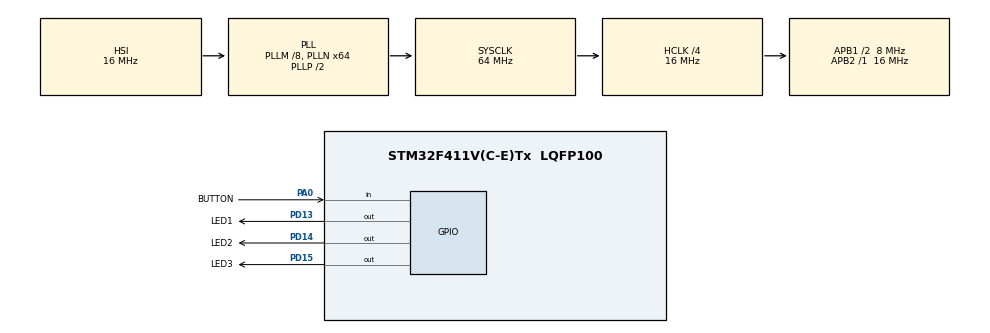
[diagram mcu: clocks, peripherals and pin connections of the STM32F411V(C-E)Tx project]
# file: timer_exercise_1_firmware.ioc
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Mcu.Family=STM32F4
Mcu.Name=STM32F411V(C-E)Tx
Mcu.Package=LQFP100
NVIC.PriorityGroup=NVIC_PRIORITYGROUP_4
NVIC.TIM2_IRQn=true\:0\:0\:false\:false\:true\:true\:true\:true
PA0-WKUP.GPIO_Label=BUTTON
PA0-WKUP.GPIO_PuPd=GPIO_PULLDOWN
PA0-WKUP.Signal=GPIO_Input
PA13.Mode=Serial_Wire
PA13.Signal=SYS_JTMS-SWDIO
PA14.Mode=Serial_Wire
PA14.Signal=SYS_JTCK-SWCLK
PD13.GPIO_Label=LED1
PD13.PinState=GPIO_PIN_SET
PD13.Signal=GPIO_Output
PD14.GPIO_Label=LED2
PD14.PinState=GPIO_PIN_SET
PD14.Signal=GPIO_Output
PD15.GPIO_Label=LED3
PD15.PinState=GPIO_PIN_SET
PD15.Signal=GPIO_Output
PH0\ -\ OSC_IN.Mode=HSE-External-Oscillator
PH0\ -\ OSC_IN.Signal=RCC_OSC_IN
PH1\ -\ OSC_OUT.Mode=HSE-External-Oscillator
PH1\ -\ OSC_OUT.Signal=RCC_OSC_OUT
ProjectManager.HeapSize=0x200
ProjectManager.StackSize=0x400
ProjectManager.TargetToolchain=STM32CubeIDE
RCC.48MHZClocksFreq_Value=32000000
RCC.AHBCLKDivider=RCC_SYSCLK_DIV4
RCC.AHBFreq_Value=16000000
RCC.APB1CLKDivider=RCC_HCLK_DIV2
RCC.APB1Freq_Value=8000000
RCC.APB1TimFreq_Value=16000000
RCC.APB2Freq_Value=16000000
RCC.APB2TimFreq_Value=16000000
RCC.CortexFreq_Value=16000000
RCC.HCLKFreq_Value=16000000
RCC.HSE_VALUE=25000000
RCC.HSI_VALUE=16000000
RCC.LSE_VALUE=32768
RCC.PLLM=8
RCC.PLLN=64
RCC.SYSCLKFreq_VALUE=64000000
RCC.SYSCLKSource=RCC_SYSCLKSOURCE_PLLCLK
RCC.VCOOutputFreq_Value=128000000
TIM2.Period=4999
TIM2.Prescaler=1599
VP_TIM2_VS_ClockSourceINT.Mode=Internal
board=custom

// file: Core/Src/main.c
/* USER CODE BEGIN Header */
/**
  ******************************************************************************
  * @file           : main.c
  * @brief          : Main program body
  ******************************************************************************
  * @attention
  *
  * Copyright (c) 2024 STMicroelectronics.
  * All rights reserved.
  *
  * This software is licensed under terms that can be found in the LICENSE file
  * in the root directory of this software component.
  * If no LICENSE file comes with this software, it is provided AS-IS.
  *
  ******************************************************************************
  */
/* USER CODE END Header */
#include "main.h"
#include "system/sys_manage.h"

#define NUMBER_OF_LEDS 3

bsp_gpio_t LED[NUMBER_OF_LEDS] = {
    {GPIOD, GPIO_PIN_13, 0, GPIO_MODE_OUTPUT_PP},
    {GPIOD, GPIO_PIN_14, 0, GPIO_MODE_OUTPUT_PP},
    {GPIOD, GPIO_PIN_15, 0, GPIO_MODE_OUTPUT_PP},
};

bsp_gpio_t BUTTON = {GPIOA, GPIO_PIN_0, 0, GPIO_MODE_INPUT};

TIM_HandleTypeDef htim2;
bool timer_flag = 0;

static sys_button_evt_t button_evt = BUTTON_EVT_NONE;

void SystemClock_Config(void);
static void MX_GPIO_Init(void);
static void MX_TIM2_Init(void);
void HAL_TIM_PeriodElapsedCallback(TIM_HandleTypeDef *htim);

int main(void)
{

  /* MCU Configuration--------------------------------------------------------*/

  /* Reset of all peripherals, Initializes the Flash interface and the Systick. */
  HAL_Init();

  /* Configure the system clock */
  SystemClock_Config();

  /* Initialize all configured peripherals */
  MX_GPIO_Init();
  MX_TIM2_Init();
  /* USER CODE BEGIN 2 */
  sys_init(&BUTTON, LED, LED_ACTIVE_LEVEL_HIGH, &htim2, 1599, 4999);
  /* USER CODE END 2 */

  /* Infinite loop */
  while (1)
  {
	button_evt = sys_button_fsm(&BUTTON);
	sys_manage_fsm(LED, LED_ACTIVE_LEVEL_HIGH, button_evt, &timer_flag);
  }
}

/**
  * @brief Callback Function of timer interrupt
  * @retval None
  */
void HAL_TIM_PeriodElapsedCallback(TIM_HandleTypeDef *htim)
{
  if (htim->Instance == TIM2)
  {
	timer_flag = 1;
  }
}

void SystemClock_Config(void)
{
  RCC_OscInitTypeDef RCC_OscInitStruct = {0};
  RCC_ClkInitTypeDef RCC_ClkInitStruct = {0};

  /** Configure the main internal regulator output voltage
  */
  __HAL_RCC_PWR_CLK_ENABLE();
  __HAL_PWR_VOLTAGESCALING_CONFIG(PWR_REGULATOR_VOLTAGE_SCALE1);

  /** Initializes the RCC Oscillators according to the specified parameters
  * in the RCC_OscInitTypeDef structure.
  */
  RCC_OscInitStruct.OscillatorType = RCC_OSCILLATORTYPE_HSI;
  RCC_OscInitStruct.HSIState = RCC_HSI_ON;
  RCC_OscInitStruct.HSICalibrationValue = RCC_HSICALIBRATION_DEFAULT;
  RCC_OscInitStruct.PLL.PLLState = RCC_PLL_ON;
  RCC_OscInitStruct.PLL.PLLSource = RCC_PLLSOURCE_HSI;
  RCC_OscInitStruct.PLL.PLLM = 8;
  RCC_OscInitStruct.PLL.PLLN = 64;
  RCC_OscInitStruct.PLL.PLLP = RCC_PLLP_DIV2;
  RCC_OscInitStruct.PLL.PLLQ = 4;
  if (HAL_RCC_OscConfig(&RCC_OscInitStruct) != HAL_OK)
  {
    Error_Handler();
  }

  /** Initializes the CPU, AHB and APB buses clocks
  */
  RCC_ClkInitStruct.ClockType = RCC_CLOCKTYPE_HCLK|RCC_CLOCKTYPE_SYSCLK
                              |RCC_CLOCKTYPE_PCLK1|RCC_CLOCKTYPE_PCLK2;
  RCC_ClkInitStruct.SYSCLKSource = RCC_SYSCLKSOURCE_PLLCLK;
  RCC_ClkInitStruct.AHBCLKDivider = RCC_SYSCLK_DIV4;
  RCC_ClkInitStruct.APB1CLKDivider = RCC_HCLK_DIV2;
  RCC_ClkInitStruct.APB2CLKDivider = RCC_HCLK_DIV1;

  if (HAL_RCC_ClockConfig(&RCC_ClkInitStruct, FLASH_LATENCY_0) != HAL_OK)
  {
    Error_Handler();
  }
}

static void MX_TIM2_Init(void)
{

  TIM_ClockConfigTypeDef sClockSourceConfig = {0};
  TIM_MasterConfigTypeDef sMasterConfig = {0};

  htim2.Instance = TIM2;
  htim2.Init.Prescaler = 1599;
  htim2.Init.CounterMode = TIM_COUNTERMODE_UP;
  htim2.Init.Period = 4999;
  htim2.Init.ClockDivision = TIM_CLOCKDIVISION_DIV1;
  htim2.Init.AutoReloadPreload = TIM_AUTORELOAD_PRELOAD_DISABLE;
  if (HAL_TIM_Base_Init(&htim2) != HAL_OK)
  {
    Error_Handler();
  }
  sClockSourceConfig.ClockSource = TIM_CLOCKSOURCE_INTERNAL;
  if (HAL_TIM_ConfigClockSource(&htim2, &sClockSourceConfig) != HAL_OK)
  {
    Error_Handler();
  }
  sMasterConfig.MasterOutputTrigger = TIM_TRGO_RESET;
  sMasterConfig.MasterSlaveMode = TIM_MASTERSLAVEMODE_DISABLE;
  if (HAL_TIMEx_MasterConfigSynchronization(&htim2, &sMasterConfig) != HAL_OK)
  {
    Error_Handler();
  }

}

static void MX_GPIO_Init(void)
{
  GPIO_InitTypeDef GPIO_InitStruct = {0};

  /* GPIO Ports Clock Enable */
  __HAL_RCC_GPIOH_CLK_ENABLE();
  __HAL_RCC_GPIOA_CLK_ENABLE();
  __HAL_RCC_GPIOD_CLK_ENABLE();

  /*Configure GPIO pin Output Level */
  HAL_GPIO_WritePin(GPIOD, LED1_Pin|LED2_Pin|LED3_Pin, GPIO_PIN_SET);

  /*Configure GPIO pin : BUTTON_Pin */
  GPIO_InitStruct.Pin = BUTTON_Pin;
  GPIO_InitStruct.Mode = GPIO_MODE_INPUT;
  GPIO_InitStruct.Pull = GPIO_PULLDOWN;
  HAL_GPIO_Init(BUTTON_GPIO_Port, &GPIO_InitStruct);

  /*Configure GPIO pins : LED1_Pin LED2_Pin LED3_Pin */
  GPIO_InitStruct.Pin = LED1_Pin|LED2_Pin|LED3_Pin;
  GPIO_InitStruct.Mode = GPIO_MODE_OUTPUT_PP;
  GPIO_InitStruct.Pull = GPIO_NOPULL;
  GPIO_InitStruct.Speed = GPIO_SPEED_FREQ_LOW;
  HAL_GPIO_Init(GPIOD, &GPIO_InitStruct);

}

void Error_Handler(void)
{
  __disable_irq();
  while (1)
  {
  }
}
